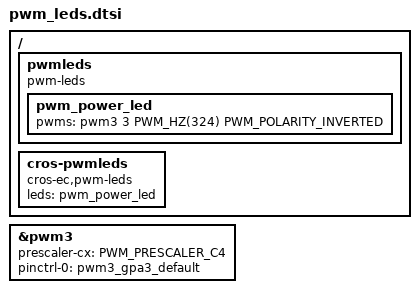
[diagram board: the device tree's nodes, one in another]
/* Copyright 2024 The ChromiumOS Authors
 * Use of this source code is governed by a BSD-style license that can be
 * found in the LICENSE file.
 */

/ {
	pwmleds {
		compatible = "pwm-leds";
		pwm_power_led: pwm_power_led {
			pwms = <&pwm3 3 PWM_HZ(324) PWM_POLARITY_INVERTED>;
		};
	};

	cros-pwmleds {
		compatible = "cros-ec,pwm-leds";

		leds = <&pwm_power_led>;
	};
};

&pwm3 {
	status = "okay";
	prescaler-cx = <PWM_PRESCALER_C4>;
	pinctrl-0 = <&pwm3_gpa3_default>;
	pinctrl-names = "default";
};
